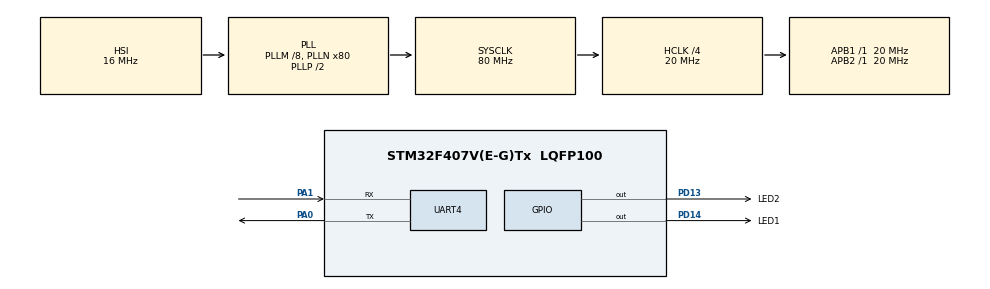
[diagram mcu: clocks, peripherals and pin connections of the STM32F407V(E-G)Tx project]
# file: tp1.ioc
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Mcu.Family=STM32F4
Mcu.Name=STM32F407V(E-G)Tx
Mcu.Package=LQFP100
NVIC.PriorityGroup=NVIC_PRIORITYGROUP_4
NVIC.TIM2_IRQn=true\:0\:0\:false\:false\:true\:true\:true\:true
NVIC.UART4_IRQn=true\:0\:0\:false\:false\:true\:true\:true\:true
PA0-WKUP.Mode=Asynchronous
PA0-WKUP.Signal=UART4_TX
PA1.Mode=Asynchronous
PA1.Signal=UART4_RX
PD13.GPIO_Label=LED2
PD13.Signal=GPIO_Output
PD14.GPIO_Label=LED1
PD14.Signal=GPIO_Output
ProjectManager.HeapSize=0x200
ProjectManager.StackSize=0x400
ProjectManager.TargetToolchain=Makefile
RCC.48MHZClocksFreq_Value=40000000
RCC.AHBCLKDivider=RCC_SYSCLK_DIV4
RCC.AHBFreq_Value=20000000
RCC.APB1Freq_Value=20000000
RCC.APB1TimFreq_Value=20000000
RCC.APB2Freq_Value=20000000
RCC.APB2TimFreq_Value=20000000
RCC.CortexFreq_Value=20000000
RCC.HCLKFreq_Value=20000000
RCC.HSE_VALUE=25000000
RCC.HSI_VALUE=16000000
RCC.LSE_VALUE=32768
RCC.PLLM=8
RCC.PLLN=80
RCC.SYSCLKFreq_VALUE=80000000
RCC.SYSCLKSource=RCC_SYSCLKSOURCE_PLLCLK
RCC.VCOOutputFreq_Value=160000000
TIM2.Period=1000
TIM2.Prescaler=20000
UART4.VirtualMode=Asynchronous
VP_TIM2_VS_ClockSourceINT.Mode=Internal
board=custom

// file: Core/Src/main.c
/* USER CODE BEGIN Header */
/**
 ******************************************************************************
 * @file           : main.c
 * @brief          : Main program body
 ******************************************************************************
 * @attention
 *
 * Copyright (c) 2022 STMicroelectronics.
 * All rights reserved.
 *
 * This software is licensed under terms that can be found in the LICENSE file
 * in the root directory of this software component.
 * If no LICENSE file comes with this software, it is provided AS-IS.
 *
 ******************************************************************************
 */
/* USER CODE END Header */
#include "main.h"

 TIM_HandleTypeDef htim2;

UART_HandleTypeDef huart4;

/* USER CODE BEGIN PV */
uint32_t counter = 0;
/* USER CODE END PV */

void SystemClock_Config(void);
static void MX_GPIO_Init(void);
static void MX_UART4_Init(void);
static void MX_TIM2_Init(void);

int main(void)
{

  /* MCU Configuration--------------------------------------------------------*/

  /* Reset of all peripherals, Initializes the Flash interface and the Systick. */
  HAL_Init();

  /* Configure the system clock */
  SystemClock_Config();

  /* Initialize all configured peripherals */
  MX_GPIO_Init();
  MX_UART4_Init();
  MX_TIM2_Init();
  /* USER CODE BEGIN 2 */
  HAL_UART_Transmit(&huart4, "init the program\n", strlen("init the program\n"), 1000);

  HAL_TIM_Base_Start_IT(&htim2);

  /* USER CODE END 2 */

  /* Infinite loop */
  /* USER CODE BEGIN WHILE */
  char buffer[100] = {0};
#define FORMAT_COUNTER "counter:%i\n"
  while (1)
  {
    HAL_Delay(1000);
    HAL_GPIO_TogglePin(LED1_GPIO_Port, LED1_Pin);
    sprintf(buffer, FORMAT_COUNTER, counter);
    HAL_UART_Transmit(&huart4, buffer, strlen(buffer), 1000);

    /* USER CODE END WHILE */

  }
}

void SystemClock_Config(void)
{
  RCC_OscInitTypeDef RCC_OscInitStruct = {0};
  RCC_ClkInitTypeDef RCC_ClkInitStruct = {0};

  /** Configure the main internal regulator output voltage
  */
  __HAL_RCC_PWR_CLK_ENABLE();
  __HAL_PWR_VOLTAGESCALING_CONFIG(PWR_REGULATOR_VOLTAGE_SCALE1);

  /** Initializes the RCC Oscillators according to the specified parameters
  * in the RCC_OscInitTypeDef structure.
  */
  RCC_OscInitStruct.OscillatorType = RCC_OSCILLATORTYPE_HSI;
  RCC_OscInitStruct.HSIState = RCC_HSI_ON;
  RCC_OscInitStruct.HSICalibrationValue = RCC_HSICALIBRATION_DEFAULT;
  RCC_OscInitStruct.PLL.PLLState = RCC_PLL_ON;
  RCC_OscInitStruct.PLL.PLLSource = RCC_PLLSOURCE_HSI;
  RCC_OscInitStruct.PLL.PLLM = 8;
  RCC_OscInitStruct.PLL.PLLN = 80;
  RCC_OscInitStruct.PLL.PLLP = RCC_PLLP_DIV2;
  RCC_OscInitStruct.PLL.PLLQ = 4;
  if (HAL_RCC_OscConfig(&RCC_OscInitStruct) != HAL_OK)
  {
    Error_Handler();
  }

  /** Initializes the CPU, AHB and APB buses clocks
  */
  RCC_ClkInitStruct.ClockType = RCC_CLOCKTYPE_HCLK|RCC_CLOCKTYPE_SYSCLK
                              |RCC_CLOCKTYPE_PCLK1|RCC_CLOCKTYPE_PCLK2;
  RCC_ClkInitStruct.SYSCLKSource = RCC_SYSCLKSOURCE_PLLCLK;
  RCC_ClkInitStruct.AHBCLKDivider = RCC_SYSCLK_DIV4;
  RCC_ClkInitStruct.APB1CLKDivider = RCC_HCLK_DIV1;
  RCC_ClkInitStruct.APB2CLKDivider = RCC_HCLK_DIV1;

  if (HAL_RCC_ClockConfig(&RCC_ClkInitStruct, FLASH_LATENCY_0) != HAL_OK)
  {
    Error_Handler();
  }
}

static void MX_TIM2_Init(void)
{

  TIM_ClockConfigTypeDef sClockSourceConfig = {0};
  TIM_MasterConfigTypeDef sMasterConfig = {0};

  htim2.Instance = TIM2;
  htim2.Init.Prescaler = 20000;
  htim2.Init.CounterMode = TIM_COUNTERMODE_UP;
  htim2.Init.Period = 1000;
  htim2.Init.ClockDivision = TIM_CLOCKDIVISION_DIV1;
  htim2.Init.AutoReloadPreload = TIM_AUTORELOAD_PRELOAD_DISABLE;
  if (HAL_TIM_Base_Init(&htim2) != HAL_OK)
  {
    Error_Handler();
  }
  sClockSourceConfig.ClockSource = TIM_CLOCKSOURCE_INTERNAL;
  if (HAL_TIM_ConfigClockSource(&htim2, &sClockSourceConfig) != HAL_OK)
  {
    Error_Handler();
  }
  sMasterConfig.MasterOutputTrigger = TIM_TRGO_RESET;
  sMasterConfig.MasterSlaveMode = TIM_MASTERSLAVEMODE_DISABLE;
  if (HAL_TIMEx_MasterConfigSynchronization(&htim2, &sMasterConfig) != HAL_OK)
  {
    Error_Handler();
  }

}

static void MX_UART4_Init(void)
{

  huart4.Instance = UART4;
  huart4.Init.BaudRate = 115200;
  huart4.Init.WordLength = UART_WORDLENGTH_8B;
  huart4.Init.StopBits = UART_STOPBITS_1;
  huart4.Init.Parity = UART_PARITY_NONE;
  huart4.Init.Mode = UART_MODE_TX_RX;
  huart4.Init.HwFlowCtl = UART_HWCONTROL_NONE;
  huart4.Init.OverSampling = UART_OVERSAMPLING_16;
  if (HAL_UART_Init(&huart4) != HAL_OK)
  {
    Error_Handler();
  }

}

static void MX_GPIO_Init(void)
{
  GPIO_InitTypeDef GPIO_InitStruct = {0};

  /* GPIO Ports Clock Enable */
  __HAL_RCC_GPIOA_CLK_ENABLE();
  __HAL_RCC_GPIOD_CLK_ENABLE();

  /*Configure GPIO pin Output Level */
  HAL_GPIO_WritePin(GPIOD, GPIO_PIN_13|GPIO_PIN_14, GPIO_PIN_RESET);

  /*Configure GPIO pins : PD13 PD14 */
  GPIO_InitStruct.Pin = GPIO_PIN_13|GPIO_PIN_14;
  GPIO_InitStruct.Mode = GPIO_MODE_OUTPUT_PP;
  GPIO_InitStruct.Pull = GPIO_NOPULL;
  GPIO_InitStruct.Speed = GPIO_SPEED_FREQ_LOW;
  HAL_GPIO_Init(GPIOD, &GPIO_InitStruct);

}

/* USER CODE BEGIN 4 */

void HAL_TIM_PeriodElapsedCallback(TIM_HandleTypeDef *htim){
  counter++;
}

/* USER CODE END 4 */

void Error_Handler(void)
{
  __disable_irq();
  while (1)
  {
  }
}
